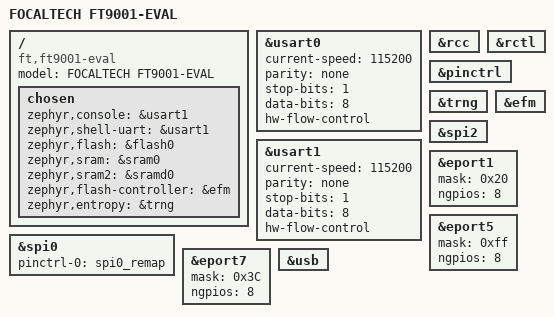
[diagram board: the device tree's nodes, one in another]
/*
 * Copyright (c) 2021, Focaltech Systems CO.,Ltd
 * SPDX-License-Identifier: Apache-2.0
 */

/dts-v1/;

#include <ft/ft90/ft9001.dtsi>
#include "ft9001_eval-pinctrl.dtsi"
#include <zephyr/dt-bindings/input/input-event-codes.h>

/ {
	model = "FOCALTECH FT9001-EVAL";
	compatible = "ft,ft9001-eval";

	chosen {
		zephyr,console = &usart1;
		zephyr,shell-uart = &usart1;
		zephyr,flash = &flash0;
		zephyr,sram = &sram0;
		zephyr,sram2 = &sramd0;
		zephyr,flash-controller = &efm;
		zephyr,entropy = &trng;
	};

};
&usart0 {
        status = "okay";
        current-speed = <115200>;
		parity = "none";
		stop-bits = "1";
		data-bits = <8>;
		hw-flow-control;
//      pinctrl-0 = <&usart0_default>;
//      pinctrl-names = "default";
};

&usart1 {
        status = "okay";
        current-speed = <115200>;
		parity = "none";
		stop-bits = "1";
		data-bits = <8>;
		hw-flow-control;
};

&rcc {
        status = "okay";
};

&rctl {
        status = "okay";
};

&pinctrl {
        status = "okay";
};

&trng {
		status = "okay";
};

&spi0 {
	status = "okay";
	pinctrl-0 = <&spi0_remap>;
    pinctrl-names = "default";
};


&spi2 {
	status = "okay";
};

&efm{
	
	status = "okay";
};

&eport1 {
	mask = <0x20>;
	ngpios = <8>;
	status = "okay";
};

&eport5 {
	mask = <0xff>;
	ngpios = <8>;
	status = "okay";
};


&eport7 {
	mask = <0x3C>;
	ngpios = <8>;
	status = "okay";
};

zephyr_udc0: &usb {
	//pinctrl-0 = <&usb_otg_hs_dm_pb14 &usb_otg_hs_dp_pb15 &usb_otg_hs_id_pb12>;
	//pinctrl-names = "default";
	status = "okay";
};
/*
&wdt0 {
	status = "okay";
};
&tc0 {
	status = "okay";
};*/
